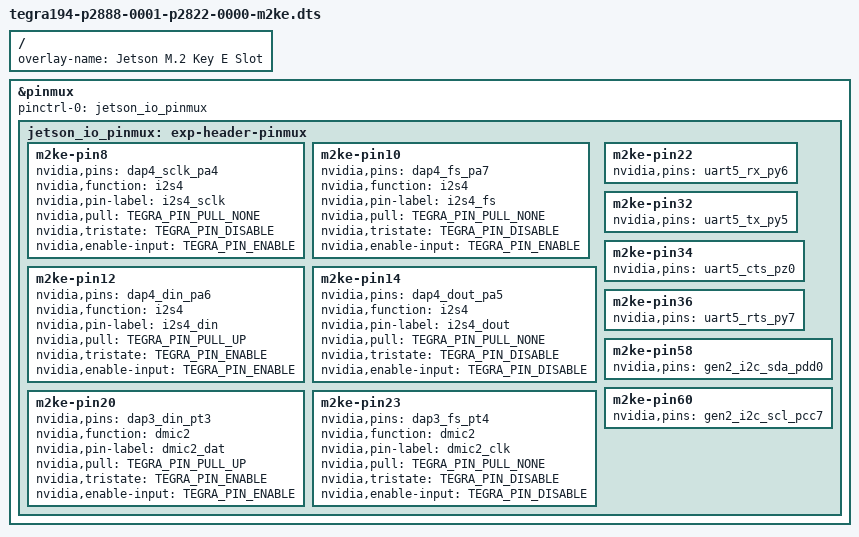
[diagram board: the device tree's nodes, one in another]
/*
 * Copyright (c) 2021, NVIDIA CORPORATION.  All rights reserved.
 *
 * This program is free software; you can redistribute it and/or modify it
 * under the terms and conditions of the GNU General Public License,
 * version 2, as published by the Free Software Foundation.
 *
 * This program is distributed in the hope it will be useful, but WITHOUT
 * ANY WARRANTY; without even the implied warranty of MERCHANTABILITY or
 * FITNESS FOR A PARTICULAR PURPOSE.  See the GNU General Public License for
 * more details.
 *
 * You should have received a copy of the GNU General Public License
 * along with this program.  If not, see <http://www.gnu.org/licenses/>.
 */

/*
 * Device-tree overlay for tegra194-p2888-0001-p2822-0000 M.2 Key E Slot.
 */

/dts-v1/;
/plugin/;

#include <dt-bindings/pinctrl/pinctrl-tegra.h>
#include <dt-common/jetson/tegra194-p2888-0001-p2822-0000.h>

/ {
	overlay-name = "Jetson M.2 Key E Slot";
	compatible = JETSON_COMPATIBLE;

	fragment@0 {
		target = <&pinmux>;
		__overlay__ {
			pinctrl-names = "default";
			pinctrl-0 = <&jetson_io_pinmux>;
			jetson_io_pinmux: exp-header-pinmux {
				m2ke-pin8 {
					nvidia,pins = "dap4_sclk_pa4";
					nvidia,function = "i2s4";
					nvidia,pin-label = "i2s4_sclk";
					nvidia,pull = <TEGRA_PIN_PULL_NONE>;
					nvidia,tristate = <TEGRA_PIN_DISABLE>;
					nvidia,enable-input = <TEGRA_PIN_ENABLE>;
				};
				m2ke-pin10 {
					nvidia,pins = "dap4_fs_pa7";
					nvidia,function = "i2s4";
					nvidia,pin-label = "i2s4_fs";
					nvidia,pull = <TEGRA_PIN_PULL_NONE>;
					nvidia,tristate = <TEGRA_PIN_DISABLE>;
					nvidia,enable-input = <TEGRA_PIN_ENABLE>;
				};
				m2ke-pin12 {
					nvidia,pins = "dap4_din_pa6";
					nvidia,function = "i2s4";
					nvidia,pin-label = "i2s4_din";
					nvidia,pull = <TEGRA_PIN_PULL_UP>;
					nvidia,tristate = <TEGRA_PIN_ENABLE>;
					nvidia,enable-input = <TEGRA_PIN_ENABLE>;
				};
				m2ke-pin14 {
					nvidia,pins = "dap4_dout_pa5";
					nvidia,function = "i2s4";
					nvidia,pin-label = "i2s4_dout";
					nvidia,pull = <TEGRA_PIN_PULL_NONE>;
					nvidia,tristate = <TEGRA_PIN_DISABLE>;
					nvidia,enable-input = <TEGRA_PIN_DISABLE>;
				};
				m2ke-pin20 {
					nvidia,pins = "dap3_din_pt3";
					nvidia,function = "dmic2";
					nvidia,pin-label = "dmic2_dat";
					nvidia,pull = <TEGRA_PIN_PULL_UP>;
					nvidia,tristate = <TEGRA_PIN_ENABLE>;
					nvidia,enable-input = <TEGRA_PIN_ENABLE>;
				};
				m2ke-pin22 {
					nvidia,pins = "uart5_rx_py6";
				};
				m2ke-pin23 {
					nvidia,pins = "dap3_fs_pt4";
					nvidia,function = "dmic2";
					nvidia,pin-label = "dmic2_clk";
					nvidia,pull = <TEGRA_PIN_PULL_NONE>;
					nvidia,tristate = <TEGRA_PIN_DISABLE>;
					nvidia,enable-input = <TEGRA_PIN_DISABLE>;
				};
				m2ke-pin32 {
					nvidia,pins = "uart5_tx_py5";
				};
				m2ke-pin34 {
					nvidia,pins = "uart5_cts_pz0";
				};
				m2ke-pin36 {
					nvidia,pins = "uart5_rts_py7";
				};
				m2ke-pin58 {
					nvidia,pins = "gen2_i2c_sda_pdd0";
				};
				m2ke-pin60 {
					nvidia,pins = "gen2_i2c_scl_pcc7";
				};
			};
		};
	};
};
